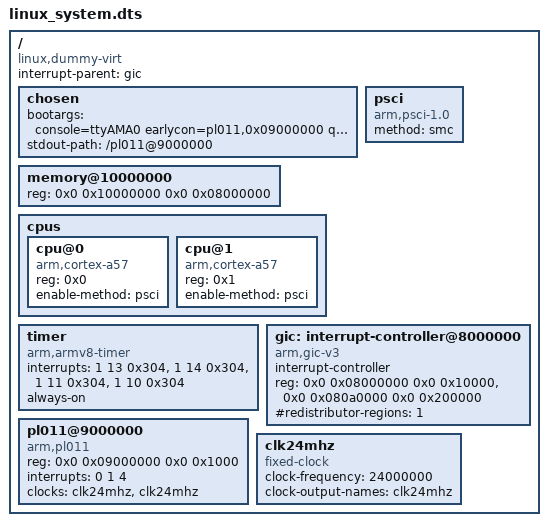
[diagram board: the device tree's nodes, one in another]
/*
 * Device tree for System Partition Linux (AArch64 hw-virt).
 * QEMU virt-compatible: GICv3, PL011 UART, ARM generic timer.
 * 128MB RAM at IPA 0x10000000, 2 vCPUs with PSCI SMP boot.
 *
 * initrd: passed via chosen node (addresses patched by boot stub or
 * kernel discovers from embedded initramfs).
 */

/dts-v1/;

/ {
	compatible = "linux,dummy-virt";
	#address-cells = <2>;
	#size-cells = <2>;
	interrupt-parent = <&gic>;

	chosen {
		bootargs = "console=ttyAMA0 earlycon=pl011,0x09000000 quiet loglevel=0 nokaslr";
		stdout-path = "/pl011@9000000";
	};

	memory@10000000 {
		device_type = "memory";
		reg = <0x0 0x10000000 0x0 0x08000000>;  /* 128MB */
	};

	cpus {
		#address-cells = <1>;
		#size-cells = <0>;

		cpu@0 {
			device_type = "cpu";
			compatible = "arm,cortex-a57";
			reg = <0x0>;
			enable-method = "psci";
		};

		cpu@1 {
			device_type = "cpu";
			compatible = "arm,cortex-a57";
			reg = <0x1>;
			enable-method = "psci";
		};
	};

	psci {
		compatible = "arm,psci-1.0", "arm,psci-0.2";
		method = "smc";
	};

	timer {
		compatible = "arm,armv8-timer";
		interrupts = <1 13 0x304>,
			     <1 14 0x304>,
			     <1 11 0x304>,
			     <1 10 0x304>;
		always-on;
	};

	gic: interrupt-controller@8000000 {
		compatible = "arm,gic-v3";
		#interrupt-cells = <3>;
		#address-cells = <2>;
		#size-cells = <2>;
		ranges;
		interrupt-controller;
		reg = <0x0 0x08000000 0x0 0x10000>,
		      <0x0 0x080a0000 0x0 0x200000>;
		#redistributor-regions = <1>;
	};

	pl011@9000000 {
		compatible = "arm,pl011", "arm,primecell";
		reg = <0x0 0x09000000 0x0 0x1000>;
		interrupts = <0 1 4>;
		clock-names = "uartclk", "apb_pclk";
		clocks = <&clk24mhz>, <&clk24mhz>;
	};

	clk24mhz: clk24mhz {
		compatible = "fixed-clock";
		#clock-cells = <0>;
		clock-frequency = <24000000>;
		clock-output-names = "clk24mhz";
	};
};
